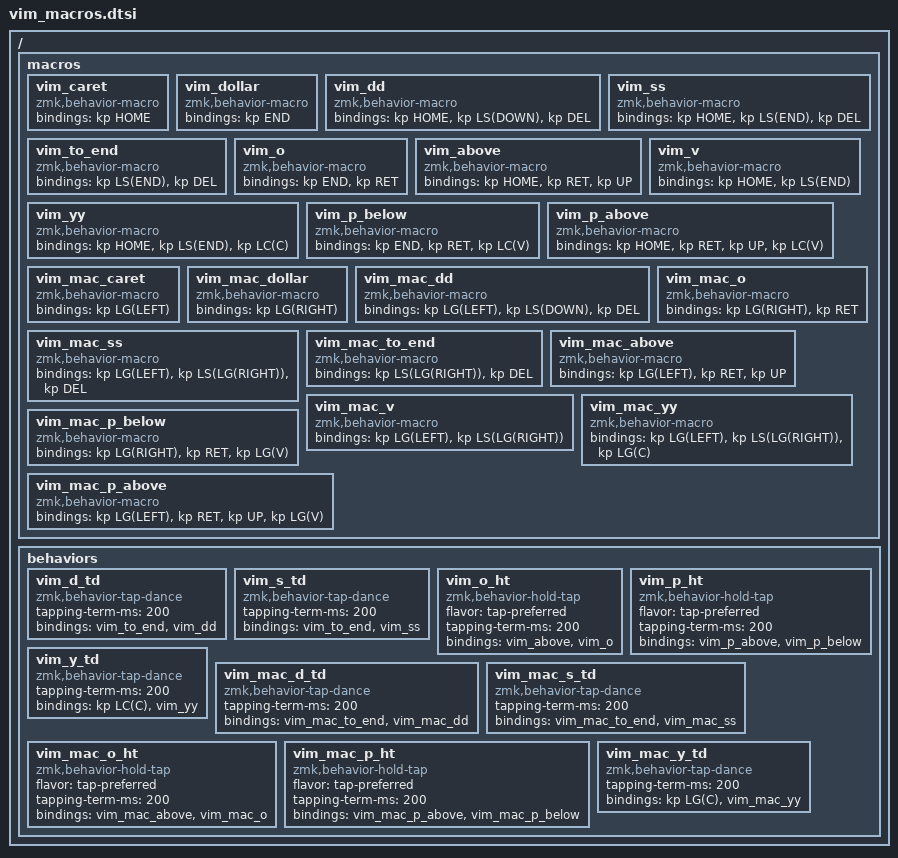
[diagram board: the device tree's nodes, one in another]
/* Vim layer macros and behaviors */
/ {
    macros {
        vim_caret: vim_caret {
            compatible = "zmk,behavior-macro";
            #binding-cells = <0>;
            bindings = <&kp HOME>;
        };
        vim_dollar: vim_dollar {
            compatible = "zmk,behavior-macro";
            #binding-cells = <0>;
            bindings = <&kp END>;
        };
        vim_dd: vim_dd {
            compatible = "zmk,behavior-macro";
            #binding-cells = <0>;
            bindings = <&kp HOME &kp LS(DOWN) &kp DEL>;
        };
        vim_ss: vim_ss {
            compatible = "zmk,behavior-macro";
            #binding-cells = <0>;
            bindings = <&kp HOME &kp LS(END) &kp DEL>;
        };
        vim_to_end: vim_to_end {
            compatible = "zmk,behavior-macro";
            #binding-cells = <0>;
            bindings = <&kp LS(END) &kp DEL>;
        };
        vim_o: vim_o {
            compatible = "zmk,behavior-macro";
            #binding-cells = <0>;
            bindings = <&kp END &kp RET>;
        };
        vim_above: vim_above {
            compatible = "zmk,behavior-macro";
            #binding-cells = <0>;
            bindings = <&kp HOME &kp RET &kp UP>;
        };
        vim_v: vim_v {
            compatible = "zmk,behavior-macro";
            #binding-cells = <0>;
            bindings = <&kp HOME &kp LS(END)>;
        };
        vim_yy: vim_yy {
            compatible = "zmk,behavior-macro";
            #binding-cells = <0>;
            bindings = <&kp HOME &kp LS(END) &kp LC(C)>;
        };
        vim_p_below: vim_p_below {
            compatible = "zmk,behavior-macro";
            #binding-cells = <0>;
            bindings = <&kp END &kp RET &kp LC(V)>;
        };
        vim_p_above: vim_p_above {
            compatible = "zmk,behavior-macro";
            #binding-cells = <0>;
            bindings = <&kp HOME &kp RET &kp UP &kp LC(V)>;
        };
    };
    behaviors {
        vim_d_td: vim_d_td {
            compatible = "zmk,behavior-tap-dance";
            #binding-cells = <0>;
            tapping-term-ms = <200>;
            bindings = <&vim_to_end>, <&vim_dd>;
        };
        vim_s_td: vim_s_td {
            compatible = "zmk,behavior-tap-dance";
            #binding-cells = <0>;
            tapping-term-ms = <200>;
            bindings = <&vim_to_end>, <&vim_ss>;
        };
        vim_o_ht: vim_o_ht {
            compatible = "zmk,behavior-hold-tap";
            #binding-cells = <2>;
            flavor = "tap-preferred";
            tapping-term-ms = <200>;
            bindings = <&vim_above>, <&vim_o>;
        };
        vim_p_ht: vim_p_ht {
            compatible = "zmk,behavior-hold-tap";
            #binding-cells = <2>;
            flavor = "tap-preferred";
            tapping-term-ms = <200>;
            bindings = <&vim_p_above>, <&vim_p_below>;
        };
        vim_y_td: vim_y_td {
            compatible = "zmk,behavior-tap-dance";
            #binding-cells = <0>;
            tapping-term-ms = <200>;
            bindings = <&kp LC(C)>, <&vim_yy>;
        };
    };
};

/* Mac vim layer macros and behaviors */
/ {
    macros {
        vim_mac_caret: vim_mac_caret {
            compatible = "zmk,behavior-macro";
            #binding-cells = <0>;
            bindings = <&kp LG(LEFT)>;
        };
        vim_mac_dollar: vim_mac_dollar {
            compatible = "zmk,behavior-macro";
            #binding-cells = <0>;
            bindings = <&kp LG(RIGHT)>;
        };
        vim_mac_dd: vim_mac_dd {
            compatible = "zmk,behavior-macro";
            #binding-cells = <0>;
            bindings = <&kp LG(LEFT) &kp LS(DOWN) &kp DEL>;
        };
        vim_mac_ss: vim_mac_ss {
            compatible = "zmk,behavior-macro";
            #binding-cells = <0>;
            bindings = <&kp LG(LEFT) &kp LS(LG(RIGHT)) &kp DEL>;
        };
        vim_mac_to_end: vim_mac_to_end {
            compatible = "zmk,behavior-macro";
            #binding-cells = <0>;
            bindings = <&kp LS(LG(RIGHT)) &kp DEL>;
        };
        vim_mac_o: vim_mac_o {
            compatible = "zmk,behavior-macro";
            #binding-cells = <0>;
            bindings = <&kp LG(RIGHT) &kp RET>;
        };
        vim_mac_above: vim_mac_above {
            compatible = "zmk,behavior-macro";
            #binding-cells = <0>;
            bindings = <&kp LG(LEFT) &kp RET &kp UP>;
        };
        vim_mac_v: vim_mac_v {
            compatible = "zmk,behavior-macro";
            #binding-cells = <0>;
            bindings = <&kp LG(LEFT) &kp LS(LG(RIGHT))>;
        };
        vim_mac_yy: vim_mac_yy {
            compatible = "zmk,behavior-macro";
            #binding-cells = <0>;
            bindings = <&kp LG(LEFT) &kp LS(LG(RIGHT)) &kp LG(C)>;
        };
        vim_mac_p_below: vim_mac_p_below {
            compatible = "zmk,behavior-macro";
            #binding-cells = <0>;
            bindings = <&kp LG(RIGHT) &kp RET &kp LG(V)>;
        };
        vim_mac_p_above: vim_mac_p_above {
            compatible = "zmk,behavior-macro";
            #binding-cells = <0>;
            bindings = <&kp LG(LEFT) &kp RET &kp UP &kp LG(V)>;
        };
    };
    behaviors {
        vim_mac_d_td: vim_mac_d_td {
            compatible = "zmk,behavior-tap-dance";
            #binding-cells = <0>;
            tapping-term-ms = <200>;
            bindings = <&vim_mac_to_end>, <&vim_mac_dd>;
        };
        vim_mac_s_td: vim_mac_s_td {
            compatible = "zmk,behavior-tap-dance";
            #binding-cells = <0>;
            tapping-term-ms = <200>;
            bindings = <&vim_mac_to_end>, <&vim_mac_ss>;
        };
        vim_mac_o_ht: vim_mac_o_ht {
            compatible = "zmk,behavior-hold-tap";
            #binding-cells = <2>;
            flavor = "tap-preferred";
            tapping-term-ms = <200>;
            bindings = <&vim_mac_above>, <&vim_mac_o>;
        };
        vim_mac_p_ht: vim_mac_p_ht {
            compatible = "zmk,behavior-hold-tap";
            #binding-cells = <2>;
            flavor = "tap-preferred";
            tapping-term-ms = <200>;
            bindings = <&vim_mac_p_above>, <&vim_mac_p_below>;
        };
        vim_mac_y_td: vim_mac_y_td {
            compatible = "zmk,behavior-tap-dance";
            #binding-cells = <0>;
            tapping-term-ms = <200>;
            bindings = <&kp LG(C)>, <&vim_mac_yy>;
        };
    };
};
